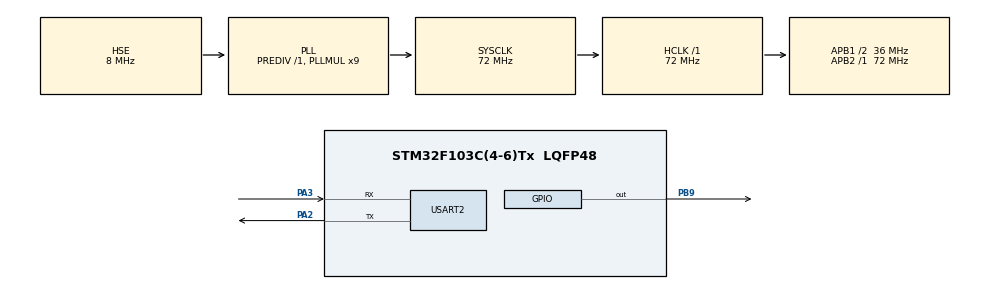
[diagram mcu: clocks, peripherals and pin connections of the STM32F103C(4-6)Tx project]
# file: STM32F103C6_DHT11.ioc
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Mcu.Family=STM32F1
Mcu.Name=STM32F103C(4-6)Tx
Mcu.Package=LQFP48
NVIC.PriorityGroup=NVIC_PRIORITYGROUP_4
PA13.Mode=Serial_Wire
PA13.Signal=SYS_JTMS-SWDIO
PA14.Mode=Serial_Wire
PA14.Signal=SYS_JTCK-SWCLK
PA2.Mode=Asynchronous
PA2.Signal=USART2_TX
PA3.Mode=Asynchronous
PA3.Signal=USART2_RX
PB9.Signal=GPIO_Output
PD0-OSC_IN.Mode=HSE-External-Oscillator
PD0-OSC_IN.Signal=RCC_OSC_IN
PD1-OSC_OUT.Mode=HSE-External-Oscillator
PD1-OSC_OUT.Signal=RCC_OSC_OUT
ProjectManager.HeapSize=0x200
ProjectManager.StackSize=0x400
ProjectManager.TargetToolchain=STM32CubeIDE
RCC.AHBFreq_Value=72000000
RCC.APB1CLKDivider=RCC_HCLK_DIV2
RCC.APB1Freq_Value=36000000
RCC.APB1TimFreq_Value=72000000
RCC.APB2Freq_Value=72000000
RCC.APB2TimFreq_Value=72000000
RCC.HCLKFreq_Value=72000000
RCC.PLLMUL=RCC_PLL_MUL9
RCC.PLLSourceVirtual=RCC_PLLSOURCE_HSE
RCC.SYSCLKFreq_VALUE=72000000
RCC.SYSCLKSource=RCC_SYSCLKSOURCE_PLLCLK
RCC.USBFreq_Value=72000000
TIM1.Prescaler=71
USART2.VirtualMode=VM_ASYNC
VP_TIM1_VS_ClockSourceINT.Mode=Internal
board=custom

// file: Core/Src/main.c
/* USER CODE BEGIN Header */
/**
  ******************************************************************************
  * @file           : main.c
  * @brief          : Main program body
  ******************************************************************************
  * @attention
  *
  * Copyright (c) 2025 STMicroelectronics.
  * All rights reserved.
  *
  * This software is licensed under terms that can be found in the LICENSE file
  * in the root directory of this software component.
  * If no LICENSE file comes with this software, it is provided AS-IS.
  *
  ******************************************************************************
  */
/* USER CODE END Header */
#include "main.h"
#include "tim.h"
#include "usart.h"
#include "gpio.h"
#include <stdio.h>

void SystemClock_Config(void);

/* USER CODE BEGIN 0 */

#define DHT11_PORT GPIOB
#define DHT11_PIN GPIO_PIN_9
uint8_t RHI, RHD, TCI, TCD, SUM;
uint32_t pMillis, cMillis;
float tCelsius = 0;
float tFahrenheit = 0;
float RH = 0;

void microDelay (uint16_t delay)
{
  __HAL_TIM_SET_COUNTER(&htim1, 0);
  while (__HAL_TIM_GET_COUNTER(&htim1) < delay);
}

uint8_t DHT11_Start (void)
{
  uint8_t Response = 0;
  GPIO_InitTypeDef GPIO_InitStructPrivate = {0};
  GPIO_InitStructPrivate.Pin = DHT11_PIN;
  GPIO_InitStructPrivate.Mode = GPIO_MODE_OUTPUT_PP;
  GPIO_InitStructPrivate.Speed = GPIO_SPEED_FREQ_LOW;
  GPIO_InitStructPrivate.Pull = GPIO_NOPULL;
  HAL_GPIO_Init(DHT11_PORT, &GPIO_InitStructPrivate); // set the pin as output
  HAL_GPIO_WritePin (DHT11_PORT, DHT11_PIN, 0);   // pull the pin low
  HAL_Delay(20);   // wait for 20ms
  HAL_GPIO_WritePin (DHT11_PORT, DHT11_PIN, 1);   // pull the pin high
  microDelay (30);   // wait for 30us
  GPIO_InitStructPrivate.Mode = GPIO_MODE_INPUT;
  GPIO_InitStructPrivate.Pull = GPIO_PULLUP;
  HAL_GPIO_Init(DHT11_PORT, &GPIO_InitStructPrivate); // set the pin as input
  microDelay (40);
  if (!(HAL_GPIO_ReadPin (DHT11_PORT, DHT11_PIN)))
  {
    microDelay (80);
    if ((HAL_GPIO_ReadPin (DHT11_PORT, DHT11_PIN))) Response = 1;
  }
  pMillis = HAL_GetTick();
  cMillis = HAL_GetTick();
  while ((HAL_GPIO_ReadPin (DHT11_PORT, DHT11_PIN)) && pMillis + 2 > cMillis)
  {
    cMillis = HAL_GetTick();
  }
  return Response;
}

uint8_t DHT11_Read (void)
{
  uint8_t a,b;
  for (a=0;a<8;a++)
  {
    pMillis = HAL_GetTick();
    cMillis = HAL_GetTick();
    while (!(HAL_GPIO_ReadPin (DHT11_PORT, DHT11_PIN)) && pMillis + 2 > cMillis)
    {  // wait for the pin to go high
      cMillis = HAL_GetTick();
    }
    microDelay (40);   // wait for 40 us
    if (!(HAL_GPIO_ReadPin (DHT11_PORT, DHT11_PIN)))   // if the pin is low
      b&= ~(1<<(7-a));
    else
      b|= (1<<(7-a));
    pMillis = HAL_GetTick();
    cMillis = HAL_GetTick();
    while ((HAL_GPIO_ReadPin (DHT11_PORT, DHT11_PIN)) && pMillis + 2 > cMillis)
    {  // wait for the pin to go low
      cMillis = HAL_GetTick();
    }
  }
  return b;
}

// Clock REG
uint32_t *pAPB2ENR    = (uint32_t*)0x40021018;
uint32_t *pAPB1ENR    = (uint32_t*)0x4002101c;

// GPIO A (PA2)
uint32_t *pGPIOACRL   = (uint32_t*)0x40010800;

// USART REG
uint32_t *pUART2_SR   = (uint32_t*)0x40004400;	// Check Status of Transmission Complete
uint32_t *pUART_2DR   = (uint32_t*)0x40004404;	//Data Present
uint32_t *pUART_2BRR  = (uint32_t*)0x40004408;	//Baud Rate Selection
uint32_t *pUART_2CR1  = (uint32_t*)0x4000440c;	//Control REG To Enable Transmission

void Uart_Write(int ch);
int __io_putchar(int ch); // Receive Char From Printf Function

void Uart2_Write(int ch){

while (!(*pUART2_SR & 0x0080)){
	// No Operation when TXE is 1 Then DR ready to get new data
}
*pUART_2DR = (ch & 0xFF);

}

int __io_putchar(int ch){

Uart2_Write(ch);
return ch;
}

/* USER CODE END 0 */

int main(void)
{

  /* MCU Configuration--------------------------------------------------------*/

  /* Reset of all peripherals, Initializes the Flash interface and the Systick. */
  HAL_Init();

  /* Configure the system clock */
  SystemClock_Config();

  /* Initialize all configured peripherals */
  MX_GPIO_Init();
  MX_TIM1_Init();
  MX_USART2_UART_Init();
  /* USER CODE BEGIN 2 */
  HAL_TIM_Base_Start(&htim1);

  /* USER CODE END 2 */

  /* Infinite loop */
  /* USER CODE BEGIN WHILE */
  printf("DHT Start.....");
  fflush(stdout);
  while (1)
  {
    /* USER CODE END WHILE */
	  printf("DHT Start.....");
	  fflush(stdout);
	  printf("DHT Start.....");
	  fflush(stdout);
	  if(DHT11_Start())
	      {
	        RHI = DHT11_Read(); // Relative humidity integral
	        RHD = DHT11_Read(); // Relative humidity decimal
	        TCI = DHT11_Read(); // Celsius integral
	        TCD = DHT11_Read(); // Celsius decimal
	        SUM = DHT11_Read(); // Check sum
	        if (RHI + RHD + TCI + TCD == SUM)
	        {
	          // Can use RHI and TCI for any purposes if whole number only needed
	          tCelsius = (float)TCI + (float)(TCD/10.0);
	          int temp = (int)TCI;
	          printf("Temperature = %d",temp);
	          fflush(stdout);
	          tFahrenheit = tCelsius * 9/5 + 32;
	          RH = (float)RHI + (float)(RHD/10.0);
	          // Can use tCelsius, tFahrenheit and RH for any purposes
	        }
	      }

  }
}

void SystemClock_Config(void)
{
  RCC_OscInitTypeDef RCC_OscInitStruct = {0};
  RCC_ClkInitTypeDef RCC_ClkInitStruct = {0};

  /** Initializes the RCC Oscillators according to the specified parameters
  * in the RCC_OscInitTypeDef structure.
  */
  RCC_OscInitStruct.OscillatorType = RCC_OSCILLATORTYPE_HSE;
  RCC_OscInitStruct.HSEState = RCC_HSE_ON;
  RCC_OscInitStruct.HSEPredivValue = RCC_HSE_PREDIV_DIV1;
  RCC_OscInitStruct.HSIState = RCC_HSI_ON;
  RCC_OscInitStruct.PLL.PLLState = RCC_PLL_ON;
  RCC_OscInitStruct.PLL.PLLSource = RCC_PLLSOURCE_HSE;
  RCC_OscInitStruct.PLL.PLLMUL = RCC_PLL_MUL9;
  if (HAL_RCC_OscConfig(&RCC_OscInitStruct) != HAL_OK)
  {
    Error_Handler();
  }

  /** Initializes the CPU, AHB and APB buses clocks
  */
  RCC_ClkInitStruct.ClockType = RCC_CLOCKTYPE_HCLK|RCC_CLOCKTYPE_SYSCLK
                              |RCC_CLOCKTYPE_PCLK1|RCC_CLOCKTYPE_PCLK2;
  RCC_ClkInitStruct.SYSCLKSource = RCC_SYSCLKSOURCE_PLLCLK;
  RCC_ClkInitStruct.AHBCLKDivider = RCC_SYSCLK_DIV1;
  RCC_ClkInitStruct.APB1CLKDivider = RCC_HCLK_DIV2;
  RCC_ClkInitStruct.APB2CLKDivider = RCC_HCLK_DIV1;

  if (HAL_RCC_ClockConfig(&RCC_ClkInitStruct, FLASH_LATENCY_2) != HAL_OK)
  {
    Error_Handler();
  }
}

void Error_Handler(void)
{
  __disable_irq();
  while (1)
  {
  }
}
